# STM32WL30 register map
File version: 1.0
CPU: CM0+ r0p0, little endian, MPU, no FPU, 4 interrupt priority bits
Registers are 32-bit, read-write, reset 0x0 unless marked. A register's access mark holds for its fields unless they carry their own. Offsets are from the block's base; [hi:lo] are bit positions; {n}, {i} and the like mark numbered series.

## GPIOA
Base 0x48000000
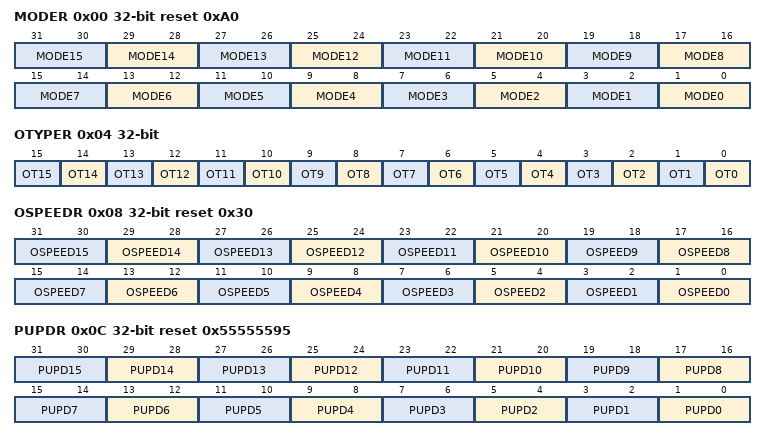
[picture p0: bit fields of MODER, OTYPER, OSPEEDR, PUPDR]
0x00 MODER reset 0xA0
  [2n+1:2n] MODE{n} (n=0..15) — MODE{n}[1:0]Port A configuration bits. These bits are written by software to configure the I/O mode. -00: Input mode -01: output mode -10: Alternate function mode -11: Analog mode
0x04 OTYPER
  [n] OT{n} (n=0..15) — OT{n}: Port A configuration bits These bits are written by software to configure the I/O output type. -0: Output push-pull (reset state) -1: Output open-drain
0x08 OSPEEDR reset 0x30
  [2n+1:2n] OSPEED{n} (n=0..15) — OSPEED{n}[1:0]: Port A configuration bits These bits are written by software to configure the I/O output speed.
0x0C PUPDR reset 0x55555595
  [2n+1:2n] PUPD{n} (n=0..15) — PUPD{n}: Port A configuration bits These bits are written by software to configure the I/O pull-up or pull-down -00: No pull-up, pull-down -01: Pull-up -10: Pull-down -11: Reserved
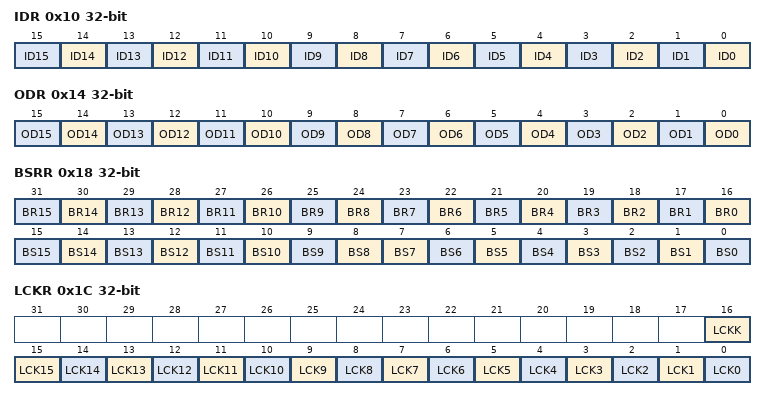
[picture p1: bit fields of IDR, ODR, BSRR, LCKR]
0x10 IDR ro
  [n] ID{n} (n=0..15) — ID{n}: Port A input data bit.These bits are read-only. They contain the input value of the corresponding I/O port
0x14 ODR
  [n] OD{n} (n=0..15) — OD{n}: Port A output data bit These bits can be read and written by software
0x18 BSRR wo
  [n+16] BR{n} (n=0..15) — BR{n}: Port A reset bit y These bits are write-only. A read to these bits returns the value 0x0000. -0: No action on the corresponding ODx bit -1: Resets the corresponding ODx bit Note: If both BSx and BRx are set, BSx has priority.
  [n] BS{n} (n=8..15) — BS{n}: Port A set bit y These bits are write-only. A read to these bits returns the value 0x0000.
  [7] BS7 — BS7: Port A set bit y These bits are write-only. A read to these bits returns the value 0x0000
  [6] BS6 — BS6: Port A set bit y These bits are write-only. A read to these bits returns the value 0x0000.
  [5] BS5 — BS5: Port A set bit y These bits are write-only. A read to these bits returns the value 0x0000
  [4] BS4 — BS4: Port A set bit y These bits are write-only. A read to these bits returns the value 0x0000.
  [3] BS3 — BS3: Port A set bit y These bits are write-only. A read to these bits returns the value 0x0000.
  [2] BS2 — BS2: Port A set bit y These bits are write-only. A read to these bits returns the value 0x0000. 0: No action on the corresponding ODx bit 1: Sets the corresponding ODx bit
  [1] BS1 — BS1: Port A set bit y These bits are write-only. A read to these bits returns the value 0x0000. 0: No action on the corresponding ODx bit 1: Sets the corresponding ODx bit
  [0] BS0 — BS0: Port A set bit y These bits are write-only. A read to these bits returns the value 0x0000. 0: No action on the corresponding ODx bit 1: Sets the corresponding ODx bit
0x1C LCKR
  [16] LCKK — LCKK: Lock key This bit can be read any time. It can only be modified using the lock key write sequence. -0: Port configuration lock key not active -1: Port configuration lock key active. The GPIOx_LCKR register is locked until the next MCU reset or peripheral reset. LOCK key write sequence: WR LCKR[16] = 1 + LCKR[15:0] WR LCKR[16] = 0 + LCKR[15:0] WR LCKR[16] = 1 + LCKR[15:0] RD LCKR RD LCKR[16] = 1 (this read operation is optional but it confirms that the lock is active) Note: During the LOCK key write sequence, the value of LCK[15:0] must not change. Any error in the lock sequence aborts the lock. After the first lock sequence on any bit of the port, any read access on the LCKK bit will return 1 until the next MCU reset or peripheral reset
  [n] LCK{n} (n=0..15) — LCK{n}: Port A lock bit {n} These bits are read/write but can only be written when the LCKK bit is 0, using the specific sequence described in LCKK bit description. -0: Port configuration not locked -1: Port configuration locked
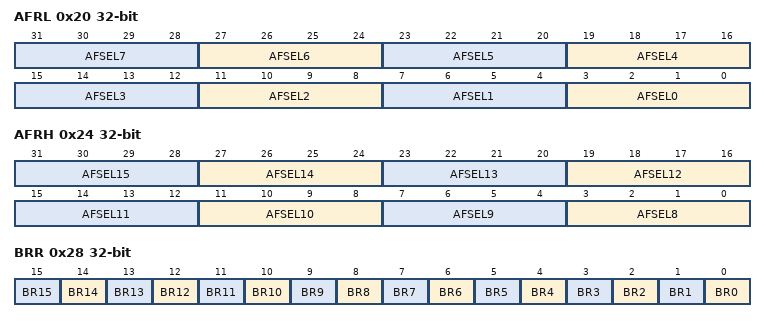
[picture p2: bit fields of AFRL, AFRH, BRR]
0x20 AFRL
  [4n+3:4n] AFSEL{n} (n=0..7) — y[3:0]: Alternate function selection for port A pin y (y = 0..7) These bits are written by software to configure alternate function I/Os AFSELy selection: -0000: AF0 -0001: AF1 -0010: AF2 -0011: AF3 -0100: AF4 -0101: AF5 -0110: AF6 -0111: AF7 1xxx: Reserved
0x24 AFRH
  [4n-29:4n-32] AFSEL{n} (n=8..15) — y[3:0]: Alternate function selection for port A pin y (y = 8..15) These bits are written by software to configure alternate function I/Os AFSELy selection: -0000: AF0 -0001: AF1 -0010: AF2 -0011: AF3 -0100: AF4 -0101: AF5 -0110: AF6 -0111: AF7 1xxx: Reserved
0x28 BRR
  [n] BR{n} wo (n=0..15) — BR{n}: Port A reset bit y (y = 0..15) These bits are write-only. A read to these bits returns the value 0x0000. -0: No action on the corresponding ODx bit -1: Resets the corresponding ODx bit

## Notices in the file
Copyright (c) 2025 STMicroelectronics.
SPDX-License-Identifier: Apache-2.0
Licensed under the Apache License, Version 2.0 (the "License");
you may not use this file except in compliance with the License.
You may obtain a copy of the License at
http://www.apache.org/licenses/LICENSE-2.0
Unless required by applicable law or agreed to in writing, software
distributed under the License is distributed on an "AS IS" BASIS,
WITHOUT WARRANTIES OR CONDITIONS OF ANY KIND, either express or implied.
See the License for the specific language governing permissions and
limitations under the License.
